# EFR32MG13P732F512GM48 register map
File version: 5.7.0
CPU: CM4 r0p1, little endian, MPU, FPU, 3 interrupt priority bits
Registers are 32-bit, read-write, reset 0x0 unless marked. A register's access mark holds for its fields unless they carry their own. Offsets are from the block's base; [hi:lo] are bit positions; {n}, {i} and the like mark numbered series.

## IDAC0
Base 0x40006000
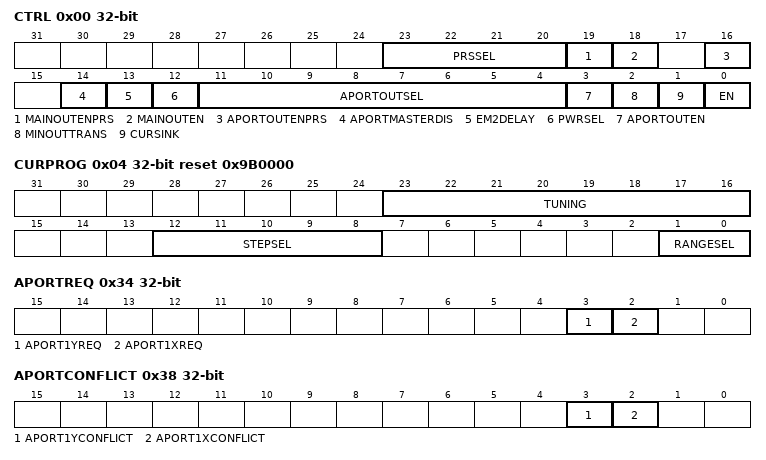
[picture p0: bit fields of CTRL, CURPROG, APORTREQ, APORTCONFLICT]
0x00 CTRL — Control Register
  [23:20] PRSSEL — IDAC Output Enable PRS Channel Select
    {v}=PRSCH{v} (PRS Channel {v} selected.) (v=0..11)
  [19] MAINOUTENPRS — PRS Controlled Main Pad Output Enable
  [18] MAINOUTEN — Output Enable
  [16] APORTOUTENPRS — PRS Controlled APORT Output Enable
  [14] APORTMASTERDIS — APORT Bus Master Disable
  [13] EM2DELAY
  [12] PWRSEL — Power Select
  [11:4] APORTOUTSEL — APORT Output Select
    32=APORT1XCH0 (APORT1X Channel 0); 33=APORT1YCH1 (APORT1Y Channel 1); 34=APORT1XCH2 (APORT1X Channel 2); 35=APORT1YCH3 (APORT1Y Channel 3); 36=APORT1XCH4 (APORT1X Channel 4); 37=APORT1YCH5 (APORT1Y Channel 5); 38=APORT1XCH6 (APORT1X Channel 6); 39=APORT1YCH7 (APORT1Y Channel 7); 40=APORT1XCH8 (APORT1X Channel 8); 41=APORT1YCH9 (APORT1Y Channel 9); 42=APORT1XCH10 (APORT1X Channel 10); 43=APORT1YCH11 (APORT1Y Channel 11); 44=APORT1XCH12 (APORT1X Channel 12); 45=APORT1YCH13 (APORT1Y Channel 13); 46=APORT1XCH14 (APORT1X Channel 14); 47=APORT1YCH15 (APORT1Y Channel 15); 48=APORT1XCH16 (APORT1X Channel 16); 49=APORT1YCH17 (APORT1Y Channel 17); 50=APORT1XCH18 (APORT1X Channel 18); 51=APORT1YCH19 (APORT1Y Channel 19); 52=APORT1XCH20 (APORT1X Channel 20); 53=APORT1YCH21 (APORT1Y Channel 21); 54=APORT1XCH22 (APORT1X Channel 22); 55=APORT1YCH23 (APORT1Y Channel 23); 56=APORT1XCH24 (APORT1X Channel 24); 57=APORT1YCH25 (APORT1Y Channel 25); 58=APORT1XCH26 (APORT1X Channel 26); 59=APORT1YCH27 (APORT1Y Channel 27); 60=APORT1XCH28 (APORT1X Channel 28); 61=APORT1YCH29 (APORT1Y Channel 29); 62=APORT1XCH30 (APORT1X Channel 30); 63=APORT1YCH31 (APORT1Y Channel 31)
  [3] APORTOUTEN — APORT Output Enable
  [2] MINOUTTRANS — Minimum Output Transition Enable
  [1] CURSINK — Current Sink Enable
  [0] EN — Current DAC Enable
0x04 CURPROG reset 0x9B0000 — Current Programming Register
  [23:16] TUNING — Tune the Current to Given Accuracy
  [12:8] STEPSEL — Current Step Size Select
  [1:0] RANGESEL — Current Range Select
    0=RANGE0 (Current range set to 0 - 1.6 uA.); 1=RANGE1 (Current range set to 1.6 - 4.7 uA.); 2=RANGE2 (Current range set to 0.5 - 16 uA.); 3=RANGE3 (Current range set to 2 - 64 uA.)
0x0C DUTYCONFIG — Duty Cycle Configuration Register
  [1] EM2DUTYCYCLEDIS — Duty Cycle Enable
0x18 STATUS ro
  [1] APORTCONFLICT — APORT Conflict Output
0x20 IF ro — Interrupt Flag Register
  [1] APORTCONFLICT — APORT Conflict Interrupt Flag
0x24 IFS wo — Interrupt Flag Set Register
  [1] APORTCONFLICT — Set APORTCONFLICT Interrupt Flag
0x28 IFC wo — Interrupt Flag Clear Register
  [1] APORTCONFLICT — Clear APORTCONFLICT Interrupt Flag
0x2C IEN — Interrupt Enable Register
  [1] APORTCONFLICT — APORTCONFLICT Interrupt Enable
0x34 APORTREQ ro — APORT Request Status Register
  [3] APORT1YREQ — 1 If the Bus Connected to APORT1Y is Requested
  [2] APORT1XREQ — 1 If the APORT Bus Connected to APORT1X is Requested
0x38 APORTCONFLICT ro — APORT Request Status Register
  [3] APORT1YCONFLICT — 1 If the Bus Connected to APORT1Y is in Conflict With Another Peripheral
  [2] APORT1XCONFLICT — 1 If the Bus Connected to APORT1X is in Conflict With Another Peripheral

## TRNG0
Base 0x4001D000
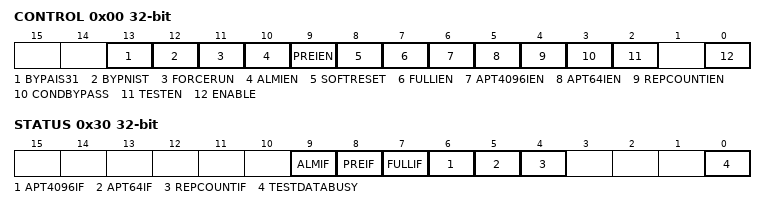
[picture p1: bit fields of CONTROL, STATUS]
0x00 CONTROL — Main Control Register
  [13] BYPAIS31 — AIS31 Start-up Test Bypass.
  [12] BYPNIST — NIST Start-up Test Bypass.
  [11] FORCERUN — Oscillator Force Run
  [10] ALMIEN — Interrupt enable for AIS31 noise alarm
  [9] PREIEN — Interrupt enable for AIS31 preliminary noise alarm
  [8] SOFTRESET — Software Reset
  [7] FULLIEN — Interrupt Enable for FIFO Full
  [6] APT4096IEN — Interrupt Enable for Adaptive Proportion Test Failure (4096-sample Window)
  [5] APT64IEN — Interrupt Enable for Adaptive Proportion Test Failure (64-sample Window)
  [4] REPCOUNTIEN — Interrupt Enable for Repetition Count Test Failure
  [3] CONDBYPASS — Conditioning Bypass
  [2] TESTEN — Test Enable
  [0] ENABLE — TRNG Module Enable
0x04 FIFOLEVEL ro read-has-side-effects
  [31:0] VALUE — FIFO Level
0x0C FIFODEPTH ro reset 0x40
  [31:0] VALUE — FIFO Depth.
{0x10+4i} KEY{i} (i=0..3) — Key Register {i}
  [31:0] VALUE — Key {i}
0x20 TESTDATA
  [31:0] VALUE — Test data input to conditioning function or to the continuous tests
0x30 STATUS
  [9] ALMIF ro — AIS31 Noise Alarm interrupt status
  [8] PREIF — AIS31 Preliminary Noise Alarm interrupt status
  [7] FULLIF ro — FIFO Full Interrupt Status
  [6] APT4096IF ro — Adaptive Proportion test failure (4096-sample window) interrupt status
  [5] APT64IF ro — Adaptive Proportion test failure (64-sample window) interrupt status
  [4] REPCOUNTIF ro — Repetition Count Test Interrupt Status
  [0] TESTDATABUSY ro
0x34 INITWAITVAL reset 0xFF — Initial Wait Counter
  [7:0] VALUE — Wait counter value
0x100 FIFO ro read-has-side-effects — FIFO Data
  [31:0] VALUE — FIFO Read Data

## Notices in the file
# License
Copyright 2018 Silicon Laboratories Inc. www.silabs.com
SPDX-License-Identifier: Zlib
The licensor of this software is Silicon Laboratories Inc.
This software is provided 'as-is', without any express or implied
warranty. In no event will the authors be held liable for any damages
arising from the use of this software.
Permission is granted to anyone to use this software for any purpose,
including commercial applications, and to alter it and redistribute it
freely, subject to the following restrictions:
1. The origin of this software must not be misrepresented; you must not
claim that you wrote the original software. If you use this software
in a product, an acknowledgment in the product documentation would be
appreciated but is not required.
2. Altered source versions must be plainly marked as such, and must not be
misrepresented as being the original software.
3. This notice may not be removed or altered from any source distribution.
